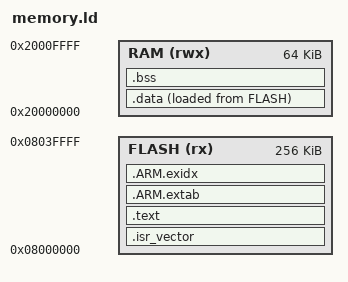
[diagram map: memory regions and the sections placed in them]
/* STM32F401CC: 256 KiB embedded FLASH and 64 KiB SRAM. */
OUTPUT_ARCH(arm)
ENTRY(Reset_Handler)

MEMORY
{
    FLASH (rx)  : ORIGIN = 0x08000000, LENGTH = 256K
    RAM   (rwx) : ORIGIN = 0x20000000, LENGTH = 64K
}

/* Initial stack pointer = konec RAM */
_estack = ORIGIN(RAM) + LENGTH(RAM);

SECTIONS
{
    /* Vector table musí být na začátku FLASH */
    .isr_vector :
    {
        . = ALIGN(4);
        KEEP(*(.isr_vector))
        . = ALIGN(4);
    } > FLASH

    /* Programový kód a read-only data */
    .text :
    {
        . = ALIGN(4);

        *(.text)
        *(.text*)
        *(.rodata)
        *(.rodata*)

        KEEP(*(.init))
        KEEP(*(.fini))

        . = ALIGN(4);
        _etext = .;
    } > FLASH

    /* ARM unwind metadata */
    .ARM.extab :
    {
        *(.ARM.extab*)
    } > FLASH

    .ARM.exidx :
    {
        __exidx_start = .;
        *(.ARM.exidx*)
        __exidx_end = .;
    } > FLASH

    /*
     * Inicializovaná data:
     * hodnoty jsou uložené ve FLASH,
     * při startu se zkopírují do RAM.
     */
    _sidata = LOADADDR(.data);

    .data :
    {
        . = ALIGN(4);
        _sdata = .;

        *(.data)
        *(.data*)

        . = ALIGN(4);
        _edata = .;
    } > RAM AT > FLASH

    /*
     * Neinicializovaná data:
     * startup je při resetu vynuluje.
     */
    .bss (NOLOAD) :
    {
        . = ALIGN(4);
        _sbss = .;

        *(.bss)
        *(.bss*)
        *(COMMON)

        . = ALIGN(4);
        _ebss = .;
    } > RAM

    /* Symboly použitelné pro heap */
    . = ALIGN(8);
    _end = .;
    end = .;

    /* Odstranění nepotřebných metadata sekcí */
    /DISCARD/ :
    {
        *(.comment)
        *(.note*)
    }
}
